# MK10D5 register map
File version: 1.6
Registers are 8-bit, read-write, reset 0x0 unless marked. A register's access mark holds for its fields unless they carry their own. Offsets are from the block's base; [hi:lo] are bit positions; {n}, {i} and the like mark numbered series; 'fields as' and 'values as' point back to an identical list.

## FTFL_FlashConfig — Flash Memory Interface
Base 0x00000400; register names take the prefix NV_
0x00 BACKKEY3 ro reset 0xFF — Backdoor Comparison Key 3.
  [7:0] KEY — Backdoor Comparison Key.
0x01 BACKKEY2 ro reset 0xFF — Backdoor Comparison Key 2.
  [7:0] KEY — Backdoor Comparison Key.
0x02 BACKKEY1 ro reset 0xFF — Backdoor Comparison Key 1.
  [7:0] KEY — Backdoor Comparison Key.
0x03 BACKKEY0 ro reset 0xFF — Backdoor Comparison Key 0.
  [7:0] KEY — Backdoor Comparison Key.
0x04 BACKKEY7 ro reset 0xFF — Backdoor Comparison Key 7.
  [7:0] KEY — Backdoor Comparison Key.
0x05 BACKKEY6 ro reset 0xFF — Backdoor Comparison Key 6.
  [7:0] KEY — Backdoor Comparison Key.
0x06 BACKKEY5 ro reset 0xFF — Backdoor Comparison Key 5.
  [7:0] KEY — Backdoor Comparison Key.
0x07 BACKKEY4 ro reset 0xFF — Backdoor Comparison Key 4.
  [7:0] KEY — Backdoor Comparison Key.
0x08 FPROT3 ro reset 0xFF — Non-volatile P-Flash Protection 1 - Low Register
  [7:0] PROT — P-Flash Region Protect
0x09 FPROT2 ro reset 0xFF — Non-volatile P-Flash Protection 1 - High Register
  [7:0] PROT — P-Flash Region Protect
0x0A FPROT1 ro reset 0xFF — Non-volatile P-Flash Protection 0 - Low Register
  [7:0] PROT — P-Flash Region Protect
0x0B FPROT0 ro reset 0xFF — Non-volatile P-Flash Protection 0 - High Register
  [7:0] PROT — P-Flash Region Protect
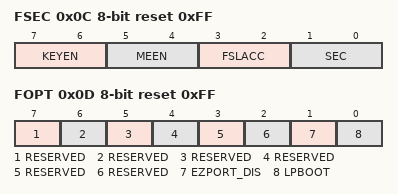
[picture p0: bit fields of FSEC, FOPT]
0x0C FSEC ro reset 0xFF — Non-volatile Flash Security Register
  [7:6] KEYEN — Backdoor Key Security Enable
  [5:4] MEEN
  [3:2] FSLACC — Freescale Failure Analysis Access Code
  [1:0] SEC — Flash Security
0x0D FOPT ro reset 0xFF — Non-volatile Flash Option Register
  [7] RESERVED, [6] RESERVED, [5] RESERVED, [4] RESERVED, [3] RESERVED, [2] RESERVED, [1] EZPORT_DIS, [0] LPBOOT
0x0E FEPROT ro reset 0xFF — Non-volatile EERAM Protection Register
  [7:0] EPROT
0x0F FDPROT ro reset 0xFF — Non-volatile D-Flash Protection Register
  [7:0] DPROT — D-Flash Region Protect

## FMC — Flash Memory Controller
Base 0x4001F000; register names take the prefix FMC_
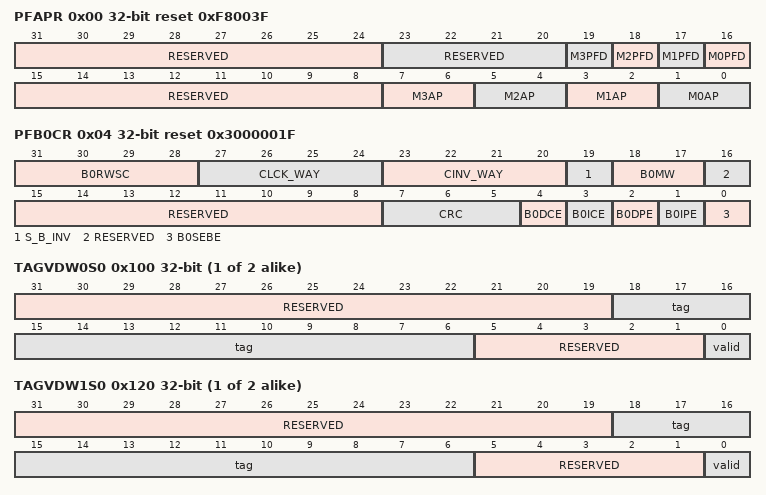
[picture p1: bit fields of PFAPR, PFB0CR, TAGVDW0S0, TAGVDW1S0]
0x00 PFAPR 32-bit access per field reset 0xF8003F — Flash Access Protection Register
  [31:24] RESERVED ro
  [23:20] RESERVED ro
  [n+16] M{n}PFD rw (n=0..3) — Master {n} Prefetch Disable
    0=Prefetching for this master is enabled; 1=Prefetching for this master is disabled
  [15:8] RESERVED ro
  [2n+1:2n] M{n}AP rw (n=0..3) — Master {n} Access Protection
    0=No access may be performed by this master; 1=Only read accesses may be performed by this master; 2=Only write accesses may be performed by this master; 3=Both read and write accesses may be performed by this master
0x04 PFB0CR 32-bit access per field reset 0x3000001F — Flash Control Register
  [31:28] B0RWSC ro — Read Wait State Control
  [27:24] CLCK_WAY rw — Cache Lock Way x
    0=Cache way is unlocked and may be displaced; 1=Cache way is locked and its contents are not displaced
  [23:20] CINV_WAY wo — Cache Invalidate Way x
    0=No cache way invalidation for the corresponding cache; 1=Invalidate cache way for the corresponding cache: clear the tag, data, and vld bits of ways selected
  [19] S_B_INV wo — Invalidate Prefetch Speculation Buffer
    0=Speculation buffer and single entry buffer are not affected; 1=Invalidate (clear) speculation buffer and single entry buffer
  [18:17] B0MW ro — Memory Width
    0=32 bits; 1=64 bits
  [16] RESERVED ro
  [15:8] RESERVED ro
  [7:5] CRC rw — Cache Replacement Control
    0=LRU replacement algorithm per set across all four ways; 2=Independent LRU with ways [0-1] for ifetches, [2-3] for data; 3=Independent LRU with ways [0-2] for ifetches, [3] for data
  [4] B0DCE rw — Data Cache Enable
    0=Do not cache data references; 1=Cache data references
  [3] B0ICE rw — Instruction Cache Enable
    0=Do not cache instruction fetches; 1=Cache instruction fetches
  [2] B0DPE rw — Data Prefetch Enable
    0=Do not prefetch in response to data references; 1=Enable prefetches in response to data references
  [1] B0IPE rw — Instruction Prefetch Enable
    0=Do not prefetch in response to instruction fetches; 1=Enable prefetches in response to instruction fetches
  [0] B0SEBE rw — Single Entry Buffer Enable
    0=Single entry buffer is disabled; 1=Single entry buffer is enabled
{0x100+4i} TAGVDW0S{i} (i=0..1) 32-bit access per field — Cache Tag Storage
  [31:19] RESERVED ro
  [18:6] tag rw — 13-bit tag for cache entry
  [5:1] RESERVED ro
  [0] valid rw — 1-bit valid for cache entry
{0x120+4i} TAGVDW1S{i} (i=0..1) 32-bit access per field — Cache Tag Storage
  fields as TAGVDW0S0
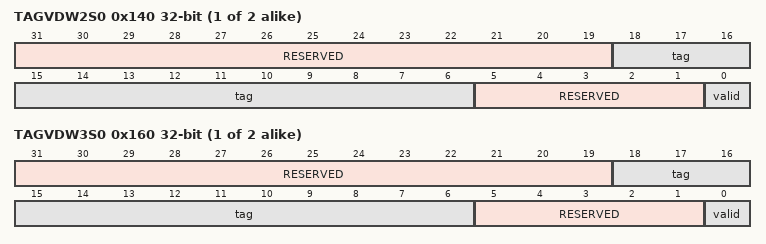
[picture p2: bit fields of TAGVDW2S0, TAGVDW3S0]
{0x140+4i} TAGVDW2S{i} (i=0..1) 32-bit access per field — Cache Tag Storage
  fields as TAGVDW0S0
{0x160+4i} TAGVDW3S{i} (i=0..1) 32-bit access per field — Cache Tag Storage
  fields as TAGVDW0S0
{0x204+8i} DATAW0S{i} (i=0..1) 32-bit — Cache Data Storage
  [31:0] data — Bits [31:0] of data entry
{0x244+8i} DATAW1S{i} (i=0..1) 32-bit — Cache Data Storage
  [31:0] data — Bits [31:0] of data entry
{0x284+8i} DATAW2S{i} (i=0..1) 32-bit — Cache Data Storage
  [31:0] data — Bits [31:0] of data entry
{0x2C4+8i} DATAW3S{i} (i=0..1) 32-bit — Cache Data Storage
  [31:0] data — Bits [31:0] of data entry
